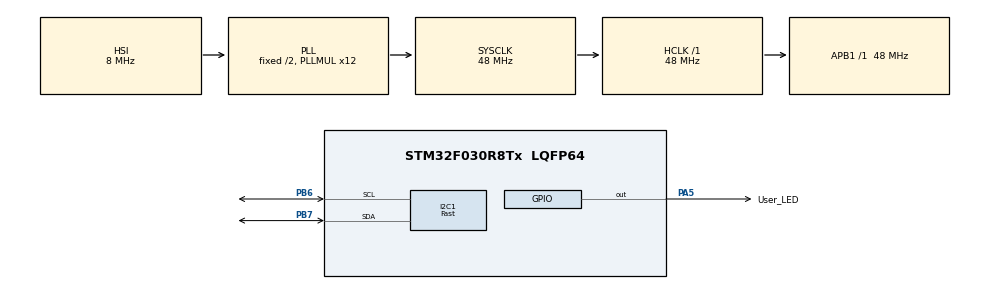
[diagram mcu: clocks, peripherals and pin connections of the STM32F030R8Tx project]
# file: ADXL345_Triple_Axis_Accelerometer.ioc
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I2C1.I2C_Speed_Mode=I2C_Fast
I2C1.Timing=0x0010020A
Mcu.Family=STM32F0
Mcu.Name=STM32F030R8Tx
Mcu.Package=LQFP64
PA13.Mode=Serial_Wire
PA13.Signal=SYS_SWDIO
PA14.Mode=Serial_Wire
PA14.Signal=SYS_SWCLK
PA5.GPIO_Label=User_LED
PA5.GPIO_Speed=GPIO_SPEED_FREQ_MEDIUM
PA5.Signal=GPIO_Output
PB6.Mode=I2C
PB6.Signal=I2C1_SCL
PB7.Mode=I2C
PB7.Signal=I2C1_SDA
ProjectManager.HeapSize=0x200
ProjectManager.StackSize=0x400
ProjectManager.TargetToolchain=STM32CubeIDE
RCC.AHBFreq_Value=48000000
RCC.APB1Freq_Value=48000000
RCC.APB1TimFreq_Value=48000000
RCC.HCLKFreq_Value=48000000
RCC.PLLMUL=RCC_PLL_MUL12
RCC.SYSCLKFreq_VALUE=48000000
RCC.SYSCLKSource=RCC_SYSCLKSOURCE_PLLCLK
board=NUCLEO-F030R8

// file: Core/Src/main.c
/* USER CODE BEGIN Header */
/**
 ******************************************************************************
 * @file           : main.c
 * @brief          : Main program body
 ******************************************************************************
 * @attention
 *
 * Copyright (c) 2026 STMicroelectronics.
 * All rights reserved.
 *
 * This software is licensed under terms that can be found in the LICENSE file
 * in the root directory of this software component.
 * If no LICENSE file comes with this software, it is provided AS-IS.
 *
 ******************************************************************************
 */
/* USER CODE END Header */
#include "main.h"

/* USER CODE BEGIN Includes */
#include "adxl345.h"	//kutuphanenin header dosyasi eklendi
/* USER CODE END Includes */

I2C_HandleTypeDef hi2c1;

/* USER CODE BEGIN PV */
//int Device_Address = 0;	//bulunan adresi atamak icin degisken yazildi //init yazildiktan sonra ihtiyac kalmadigi icin yoruma cekilir.
ADXL345_INIT_STATUS Result;	//sonuclari kayit etmek icin olusturuldu
int16_t X_Value=0, Y_Value=0, Z_Value=0 ;	//x,y,z eksenlerindeki ivmelenme degerlerini kayit etmek icin olusturuldu
float G_X_Value=0, G_Y_Value=0, G_Z_Value=0 ;	//x,y,z eksenlerindeki ivmelenme degerlerini G cinsinden kayit etmek icin olusturuldu
/* USER CODE END PV */

void SystemClock_Config(void);
static void MX_GPIO_Init(void);
static void MX_I2C1_Init(void);

int main(void) {

	/* MCU Configuration--------------------------------------------------------*/

	/* Reset of all peripherals, Initializes the Flash interface and the Systick. */
	HAL_Init();

	/* Configure the system clock */
	SystemClock_Config();

	/* Initialize all configured peripherals */
	MX_GPIO_Init();
	MX_I2C1_Init();
	/* USER CODE BEGIN 2 */
	//Device_Address = ADXL345_Scan_Device_ID(); //bu kodu calistirip i2c bagli olan modulun adresini debug yaparken live expressions dan aliriz. daha sonra init icinde kullanacagimiz icin yoruma cekeriz
	Result = ADXL345_Init(&hi2c1);	//sensorde bir hata varsa INIT_FAIL doner ve kod calismayi durdurur. INIT_SUCCESS donerse kod calisiyordur.

	/* USER CODE END 2 */

	/* Infinite loop */
	while (1) {

		/* USER CODE BEGIN 3 */
		X_Value=ADXL345_Get_Axis_Value(&hi2c1, X);	//x eksenindeki verileri al
		Y_Value=ADXL345_Get_Axis_Value(&hi2c1, Y);	//y eksenindeki verileri al
		Z_Value=ADXL345_Get_Axis_Value(&hi2c1, Z);	//z eksenindeki verileri al

		G_X_Value=ADXL345_Get_G_Value(&hi2c1, X, SCALE_FACTOR_4G);	//x eksenindeki verileri alip G cinsine cevir
		G_Y_Value=ADXL345_Get_G_Value(&hi2c1, Y, SCALE_FACTOR_4G);	//y eksenindeki verileri alip G cinsine cevir
		G_Z_Value=ADXL345_Get_G_Value(&hi2c1, Z, SCALE_FACTOR_4G);	//z eksenindeki verileri alip G cinsine cevir

		HAL_GPIO_WritePin(User_LED_GPIO_Port, User_LED_Pin, GPIO_PIN_SET);	//son olarak kullanici LED ini yak
	}
	/* USER CODE END 3 */
}

void SystemClock_Config(void) {
	RCC_OscInitTypeDef RCC_OscInitStruct = { 0 };
	RCC_ClkInitTypeDef RCC_ClkInitStruct = { 0 };
	RCC_PeriphCLKInitTypeDef PeriphClkInit = { 0 };

	/** Initializes the RCC Oscillators according to the specified parameters
	 * in the RCC_OscInitTypeDef structure.
	 */
	RCC_OscInitStruct.OscillatorType = RCC_OSCILLATORTYPE_HSI;
	RCC_OscInitStruct.HSIState = RCC_HSI_ON;
	RCC_OscInitStruct.HSICalibrationValue = RCC_HSICALIBRATION_DEFAULT;
	RCC_OscInitStruct.PLL.PLLState = RCC_PLL_ON;
	RCC_OscInitStruct.PLL.PLLSource = RCC_PLLSOURCE_HSI;
	RCC_OscInitStruct.PLL.PLLMUL = RCC_PLL_MUL12;
	RCC_OscInitStruct.PLL.PREDIV = RCC_PREDIV_DIV1;
	if (HAL_RCC_OscConfig(&RCC_OscInitStruct) != HAL_OK) {
		Error_Handler();
	}

	/** Initializes the CPU, AHB and APB buses clocks
	 */
	RCC_ClkInitStruct.ClockType = RCC_CLOCKTYPE_HCLK | RCC_CLOCKTYPE_SYSCLK
			| RCC_CLOCKTYPE_PCLK1;
	RCC_ClkInitStruct.SYSCLKSource = RCC_SYSCLKSOURCE_PLLCLK;
	RCC_ClkInitStruct.AHBCLKDivider = RCC_SYSCLK_DIV1;
	RCC_ClkInitStruct.APB1CLKDivider = RCC_HCLK_DIV1;

	if (HAL_RCC_ClockConfig(&RCC_ClkInitStruct, FLASH_LATENCY_1) != HAL_OK) {
		Error_Handler();
	}
	PeriphClkInit.PeriphClockSelection = RCC_PERIPHCLK_I2C1;
	PeriphClkInit.I2c1ClockSelection = RCC_I2C1CLKSOURCE_HSI;
	if (HAL_RCCEx_PeriphCLKConfig(&PeriphClkInit) != HAL_OK) {
		Error_Handler();
	}
}

static void MX_I2C1_Init(void) {

	hi2c1.Instance = I2C1;
	hi2c1.Init.Timing = 0x0010020A;
	hi2c1.Init.OwnAddress1 = 0;
	hi2c1.Init.AddressingMode = I2C_ADDRESSINGMODE_7BIT;
	hi2c1.Init.DualAddressMode = I2C_DUALADDRESS_DISABLE;
	hi2c1.Init.OwnAddress2 = 0;
	hi2c1.Init.OwnAddress2Masks = I2C_OA2_NOMASK;
	hi2c1.Init.GeneralCallMode = I2C_GENERALCALL_DISABLE;
	hi2c1.Init.NoStretchMode = I2C_NOSTRETCH_DISABLE;
	if (HAL_I2C_Init(&hi2c1) != HAL_OK) {
		Error_Handler();
	}

	/** Configure Analogue filter
	 */
	if (HAL_I2CEx_ConfigAnalogFilter(&hi2c1, I2C_ANALOGFILTER_ENABLE)
			!= HAL_OK) {
		Error_Handler();
	}

	/** Configure Digital filter
	 */
	if (HAL_I2CEx_ConfigDigitalFilter(&hi2c1, 0) != HAL_OK) {
		Error_Handler();
	}

}

static void MX_GPIO_Init(void) {
	GPIO_InitTypeDef GPIO_InitStruct = { 0 };

	/* GPIO Ports Clock Enable */
	__HAL_RCC_GPIOA_CLK_ENABLE();
	__HAL_RCC_GPIOB_CLK_ENABLE();

	/*Configure GPIO pin Output Level */
	HAL_GPIO_WritePin(User_LED_GPIO_Port, User_LED_Pin, GPIO_PIN_RESET);

	/*Configure GPIO pin : User_LED_Pin */
	GPIO_InitStruct.Pin = User_LED_Pin;
	GPIO_InitStruct.Mode = GPIO_MODE_OUTPUT_PP;
	GPIO_InitStruct.Pull = GPIO_NOPULL;
	GPIO_InitStruct.Speed = GPIO_SPEED_FREQ_MEDIUM;
	HAL_GPIO_Init(User_LED_GPIO_Port, &GPIO_InitStruct);

}

void Error_Handler(void) {
	__disable_irq();
	while (1) {
	}
}
